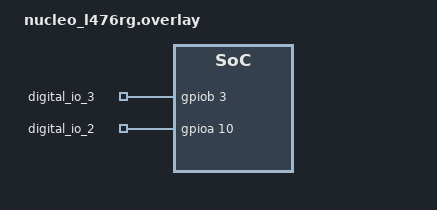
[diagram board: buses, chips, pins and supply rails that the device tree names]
/*
 * Copyright (c) 2024 8tronix GmbH. All rights reserved.
 */
/
{
	aliases
  {
	};

	chosen
  {
	};

	digital_io
	{
		compatible = "gpio-keys";

		/*
		digital_io_7: digital_io_7 {
				signal-gpios = <&gpioa 8 GPIO_ACTIVE_HIGH>;
		};
		digital_io_6: digital_io_6 {
				signal-gpios = <&gpiob 10 GPIO_ACTIVE_HIGH>;
		};
		digital_io_5: digital_io_5 {
				signal-gpios = <&gpiob 4 GPIO_ACTIVE_HIGH>;
		};
		digital_io_4: digital_io_4 {
				signal-gpios = <&gpiob 5 GPIO_ACTIVE_HIGH>;
		};*/
		digital_io_3: digital_io_3 {
				gpios = <&gpiob 3 GPIO_ACTIVE_HIGH>;
		};
		digital_io_2: digital_io_2 {
				gpios = <&gpioa 10 GPIO_ACTIVE_HIGH>;
		};
		/*digital_io_1 {
			gpios = <&gpioa 2 GPIO_ACTIVE_HIGH>;
		};
		digital_io_0 {
			gpios  = <&gpioa 3 GPIO_ACTIVE_HIGH>;
		}; */
	};
};
